# STM32G491 register map
File version: 1.9
CPU: CM4 r0p1, little endian, MPU, FPU, 4 interrupt priority bits
Registers are 32-bit, read-write, reset 0x0 unless marked. A register's access mark holds for its fields unless they carry their own. Offsets are from the block's base; [hi:lo] are bit positions; {n}, {i} and the like mark numbered series.

## FMAC — Filter Math Accelerator
Base 0x40021400
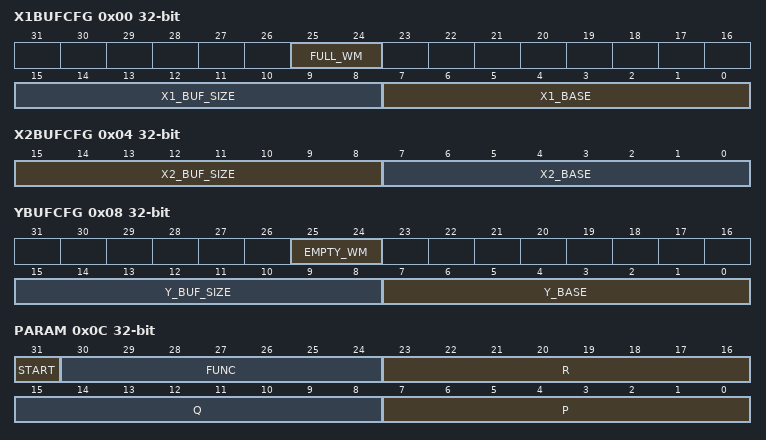
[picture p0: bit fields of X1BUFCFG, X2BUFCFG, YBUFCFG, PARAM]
0x00 X1BUFCFG — FMAC X1 Buffer Configuration register
  [25:24] FULL_WM, [15:8] X1_BUF_SIZE, [7:0] X1_BASE
0x04 X2BUFCFG — FMAC X2 Buffer Configuration register
  [15:8] X2_BUF_SIZE — X1_BUF_SIZE
  [7:0] X2_BASE — X1_BASE
0x08 YBUFCFG — FMAC Y Buffer Configuration register
  [25:24] EMPTY_WM
  [15:8] Y_BUF_SIZE — X1_BUF_SIZE
  [7:0] Y_BASE — X1_BASE
0x0C PARAM — FMAC Parameter register
  [31] START, [30:24] FUNC, [23:16] R, [15:8] Q, [7:0] P
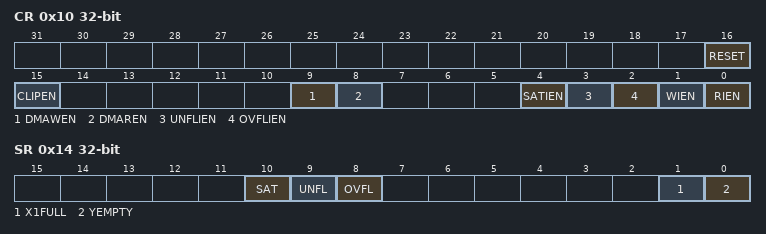
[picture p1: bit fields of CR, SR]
0x10 CR — FMAC Control register
  [16] RESET, [15] CLIPEN, [9] DMAWEN, [8] DMAREN, [4] SATIEN, [3] UNFLIEN, [2] OVFLIEN, [1] WIEN, [0] RIEN
0x14 SR ro — FMAC Status register
  [10] SAT, [9] UNFL, [8] OVFL, [1] X1FULL, [0] YEMPTY
0x18 WDATA wo — FMAC Write Data register
  [15:0] WDATA
0x1C RDATA ro — FMAC Read Data register
  [15:0] RDATA

## CORDIC — CORDIC Co-processor
Base 0x40020C00
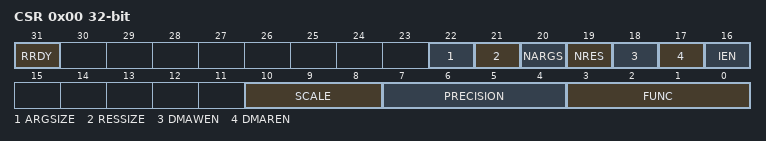
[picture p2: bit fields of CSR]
0x00 CSR — CORDIC Control Status register
  [31] RRDY
    on read: 0=NotReady (Results from computation are not read); 1=Ready (Results are ready, this flag will be automatically cleared once value is read)
  [22] ARGSIZE
    0=Bits32 (Use 32 bit input values); 1=Bits16 (Use 16 bit input values)
  [21] RESSIZE
    0=Bits32 (Use 32 bit output values); 1=Bits16 (Use 16 bit output values)
  [20] NARGS
    0=Num1 (Only single argument write is needed for next calculation); 1=Num2 (Two argument writes need to be performed for next calculation)
  [19] NRES
    0=Num1 (Only single result value will be returned. After a single read RRDY will be automatically cleared); 1=Num2 (Two return reads need to be performed. After two reads RRDY will be automatically cleared)
  [18] DMAWEN
    0=Disabled (No DMA channel writes are generated); 1=Enabled (Write requests are generated on the DMA channel when no operation is pending)
  [17] DMAREN
    0=Disabled (No DMA channel reads are generated); 1=Enabled (Read requests are generated on the DMA channel when RRDY flag is set)
  [16] IEN
    0=Disabled (Disable interrupt request generation); 1=Enabled (Enable interrupt request generation)
  [10:8] SCALE — Scaling factor (2^-n for arguments, 2^n for results)
  [7:4] PRECISION — Precision (number of iterations/cycles) required
    1=Iters4 (4 iterations); 2=Iters8 (8 iterations); 3=Iters12 (12 iterations); 4=Iters16 (16 iterations); 5=Iters20 (20 iterations); 6=Iters24 (24 iterations); 7=Iters28 (28 iterations); 8=Iters32 (32 iterations); 9=Iters36 (36 iterations); 10=Iters40 (40 iterations); 11=Iters44 (44 iterations); 12=Iters48 (48 iterations); 13=Iters52 (52 iterations); 14=Iters56 (56 iterations); 15=Iters60 (60 iterations)
  [3:0] FUNC
    0=Cosine function; 1=Sine function; 2=Phase function; 3=Modulus function; 4=Arctangent function; 5=Hyperbolic Cosine function; 6=Hyperbolic Sine function; 7=Arctanh function; 8=Natural Logarithm function; 9=Square Root function
0x04 WDATA — CORDIC argument register
  [31:0] ARG
0x08 RDATA ro — CORDIC result register
  [31:0] RES

## TAMP — Tamper and backup registers
Base 0x40002400
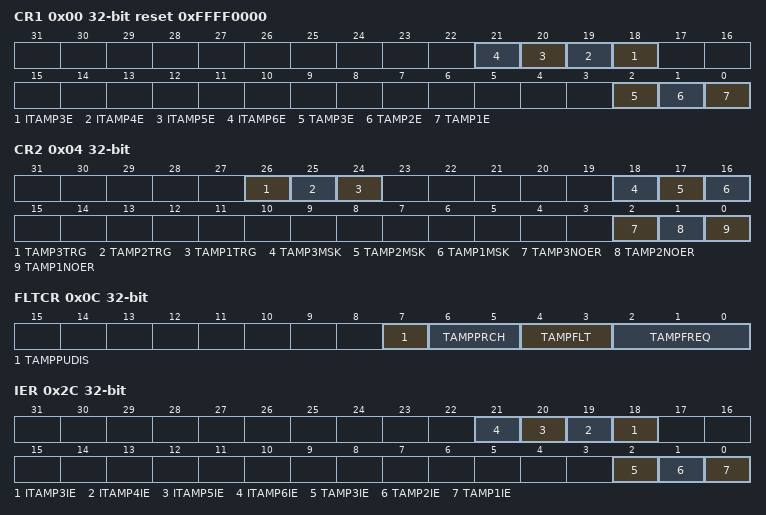
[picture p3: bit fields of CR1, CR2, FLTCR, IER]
0x00 CR1 reset 0xFFFF0000 — control register 1
  [n+15] ITAMP{n}E (n=3..6)
  [2] TAMP3E — TAMP2E
  [1] TAMP2E
  [0] TAMP1E
0x04 CR2 — control register 2
  [26] TAMP3TRG, [25] TAMP2TRG, [24] TAMP1TRG, [18] TAMP3MSK, [17] TAMP2MSK, [16] TAMP1MSK, [2] TAMP3NOER, [1] TAMP2NOER, [0] TAMP1NOER
0x0C FLTCR — TAMP filter control register
  [7] TAMPPUDIS, [6:5] TAMPPRCH, [4:3] TAMPFLT, [2:0] TAMPFREQ
0x2C IER — TAMP interrupt enable register
  [n+15] ITAMP{n}IE (n=3..6), [2] TAMP3IE, [1] TAMP2IE, [0] TAMP1IE
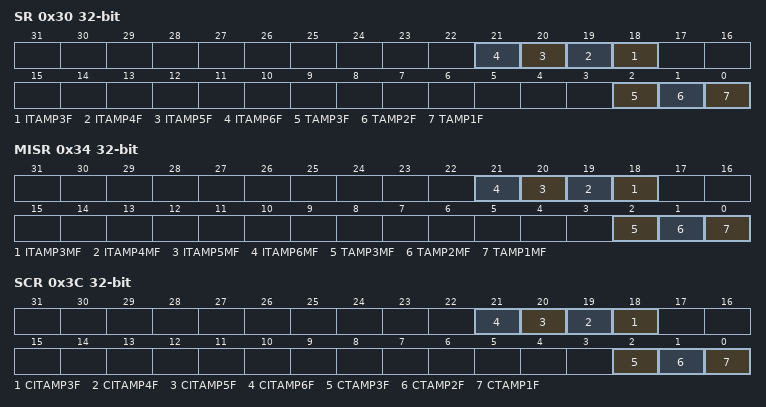
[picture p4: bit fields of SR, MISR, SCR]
0x30 SR ro — TAMP status register
  [n+15] ITAMP{n}F (n=3..6), [2] TAMP3F, [1] TAMP2F, [0] TAMP1F
0x34 MISR ro — TAMP masked interrupt status register
  [n+15] ITAMP{n}MF (n=3..6), [2] TAMP3MF, [1] TAMP2MF, [0] TAMP1MF
0x3C SCR — TAMP status clear register
  [n+15] CITAMP{n}F (n=3..6), [2] CTAMP3F, [1] CTAMP2F, [0] CTAMP1F
{0x100+4i} BKP{i}R (i=0..31) — TAMP backup register
  [31:0] BKP
